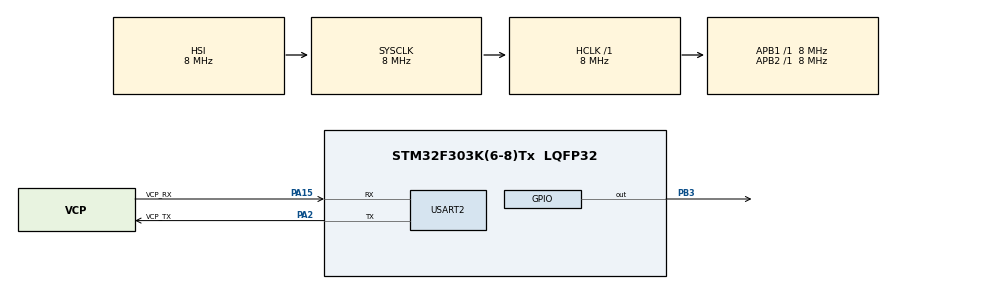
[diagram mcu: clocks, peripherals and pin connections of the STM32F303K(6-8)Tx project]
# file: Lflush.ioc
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Mcu.Family=STM32F3
Mcu.Name=STM32F303K(6-8)Tx
Mcu.Package=LQFP32
Mcu.UserConstants=PWMG,htim1
NVIC.PriorityGroup=NVIC_PRIORITYGROUP_4
NVIC.USART2_IRQn=true\:0\:0\:false\:false\:true\:true\:true
PA13.GPIO_Label=SWDIO
PA13.Mode=Serial_Wire
PA13.Signal=SYS_JTMS-SWDIO
PA14.GPIO_Label=SWCLK
PA14.Mode=Serial_Wire
PA14.Signal=SYS_JTCK-SWCLK
PA15.GPIO_Label=VCP_RX
PA15.Mode=Asynchronous
PA15.Signal=USART2_RX
PA2.GPIO_Label=VCP_TX
PA2.Mode=Asynchronous
PA2.Signal=USART2_TX
PB3.Signal=GPIO_Output
PF0\ /\ OSC_IN.GPIO_Label=MCO
PF0\ /\ OSC_IN.Mode=HSE-External-Clock-Source
PF0\ /\ OSC_IN.Signal=RCC_OSC_IN
ProjectManager.HeapSize=0x200
ProjectManager.StackSize=0x400
ProjectManager.TargetToolchain=STM32CubeIDE
RCC.AHBFreq_Value=8000000
RCC.APB1Freq_Value=8000000
RCC.APB2Freq_Value=8000000
RCC.CortexFreq_Value=8000000
RCC.HSE_VALUE=8000000
RCC.HSI_VALUE=8000000
RCC.PLLMUL=RCC_PLL_MUL4
RCC.SYSCLKFreq_VALUE=8000000
USART2.OneBitSampling=UART_ONE_BIT_SAMPLE_DISABLE
USART2.OverSampling=UART_OVERSAMPLING_16
USART2.VirtualMode-Asynchronous=VM_ASYNC
board=NUCLEO-F303K8

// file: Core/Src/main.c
/* USER CODE BEGIN Header */
/**
  ******************************************************************************
  * @file           : main.c
  * @brief          : Main program body
  ******************************************************************************
  * @attention
  *
  * <h2><center>&copy; Copyright (c) 2020 STMicroelectronics.
  * All rights reserved.</center></h2>
  *
  * This software component is licensed by ST under BSD 3-Clause license,
  * the "License"; You may not use this file except in compliance with the
  * License. You may obtain a copy of the License at:
  *                        opensource.org/licenses/BSD-3-Clause
  *
  ******************************************************************************
  */
/* USER CODE END Header */
#include "main.h"

UART_HandleTypeDef huart2;

void SystemClock_Config(void);
static void MX_GPIO_Init(void);
static void MX_USART2_UART_Init(void);

int main(void)
{

  /* MCU Configuration--------------------------------------------------------*/

  /* Reset of all peripherals, Initializes the Flash interface and the Systick. */
  HAL_Init();

  /* Configure the system clock */
  SystemClock_Config();

  /* Initialize all configured peripherals */
  MX_GPIO_Init();
  MX_USART2_UART_Init();

  /* Infinite loop */
  /* USER CODE BEGIN WHILE */
  const uint8_t pre[]= "Please input >";
  uint8_t res[]= "\r\n Input is x\r\n";
  uint8_t inp;
  while (1)
  {
	  HAL_UART_Transmit(&huart2,pre,strlen(pre),HAL_MAX_DELAY);
	  HAL_UART_Receive(&huart2,&inp,1, HAL_MAX_DELAY);
	  res[12] = inp;
	  HAL_UART_Transmit(&huart2,res,strlen(res), HAL_MAX_DELAY);

	  //const uint8_t data[]= "Hello World!!\r\n";
	  //uint16_t length = strlen(data);

	  //HAL_GPIO_TogglePin(GPIOB,GPIO_PIN_3);
	  //for(int i = 0;i < 500;i++){
	//	  HAL_UART_Transmit(&huart2,data,length,HAL_MAX_DELAY);
	  //	  HAL_Delay(1);
	  //}
    /* USER CODE END WHILE */

  }
}

void SystemClock_Config(void)
{
  RCC_OscInitTypeDef RCC_OscInitStruct = {0};
  RCC_ClkInitTypeDef RCC_ClkInitStruct = {0};

  /** Initializes the RCC Oscillators according to the specified parameters
  * in the RCC_OscInitTypeDef structure.
  */
  RCC_OscInitStruct.OscillatorType = RCC_OSCILLATORTYPE_HSI;
  RCC_OscInitStruct.HSIState = RCC_HSI_ON;
  RCC_OscInitStruct.HSICalibrationValue = RCC_HSICALIBRATION_DEFAULT;
  RCC_OscInitStruct.PLL.PLLState = RCC_PLL_NONE;
  if (HAL_RCC_OscConfig(&RCC_OscInitStruct) != HAL_OK)
  {
    Error_Handler();
  }
  /** Initializes the CPU, AHB and APB buses clocks
  */
  RCC_ClkInitStruct.ClockType = RCC_CLOCKTYPE_HCLK|RCC_CLOCKTYPE_SYSCLK
                              |RCC_CLOCKTYPE_PCLK1|RCC_CLOCKTYPE_PCLK2;
  RCC_ClkInitStruct.SYSCLKSource = RCC_SYSCLKSOURCE_HSI;
  RCC_ClkInitStruct.AHBCLKDivider = RCC_SYSCLK_DIV1;
  RCC_ClkInitStruct.APB1CLKDivider = RCC_HCLK_DIV1;
  RCC_ClkInitStruct.APB2CLKDivider = RCC_HCLK_DIV1;

  if (HAL_RCC_ClockConfig(&RCC_ClkInitStruct, FLASH_LATENCY_0) != HAL_OK)
  {
    Error_Handler();
  }
}

static void MX_USART2_UART_Init(void)
{

  huart2.Instance = USART2;
  huart2.Init.BaudRate = 38400;
  huart2.Init.WordLength = UART_WORDLENGTH_8B;
  huart2.Init.StopBits = UART_STOPBITS_1;
  huart2.Init.Parity = UART_PARITY_NONE;
  huart2.Init.Mode = UART_MODE_TX_RX;
  huart2.Init.HwFlowCtl = UART_HWCONTROL_NONE;
  huart2.Init.OverSampling = UART_OVERSAMPLING_16;
  huart2.Init.OneBitSampling = UART_ONE_BIT_SAMPLE_DISABLE;
  huart2.AdvancedInit.AdvFeatureInit = UART_ADVFEATURE_NO_INIT;
  if (HAL_UART_Init(&huart2) != HAL_OK)
  {
    Error_Handler();
  }

}

static void MX_GPIO_Init(void)
{
  GPIO_InitTypeDef GPIO_InitStruct = {0};

  /* GPIO Ports Clock Enable */
  __HAL_RCC_GPIOF_CLK_ENABLE();
  __HAL_RCC_GPIOA_CLK_ENABLE();
  __HAL_RCC_GPIOB_CLK_ENABLE();

  /*Configure GPIO pin Output Level */
  HAL_GPIO_WritePin(GPIOB, GPIO_PIN_3, GPIO_PIN_RESET);

  /*Configure GPIO pin : PB3 */
  GPIO_InitStruct.Pin = GPIO_PIN_3;
  GPIO_InitStruct.Mode = GPIO_MODE_OUTPUT_PP;
  GPIO_InitStruct.Pull = GPIO_NOPULL;
  GPIO_InitStruct.Speed = GPIO_SPEED_FREQ_LOW;
  HAL_GPIO_Init(GPIOB, &GPIO_InitStruct);

}

void Error_Handler(void)
{
}

/************************ (C) COPYRIGHT STMicroelectronics *****END OF FILE****/
